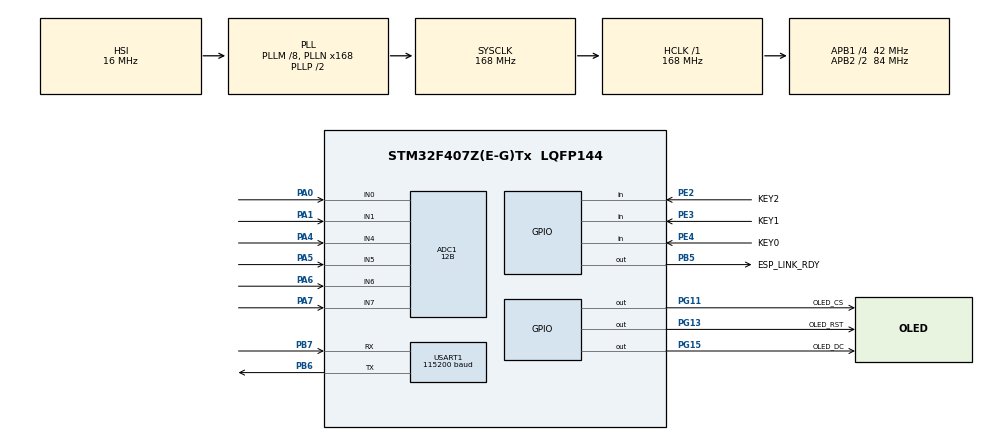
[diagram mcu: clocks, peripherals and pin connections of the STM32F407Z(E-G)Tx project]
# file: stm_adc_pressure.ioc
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ADC1.Channel-1\#ChannelRegularConversion=ADC_CHANNEL_0
ADC1.Channel-2\#ChannelRegularConversion=ADC_CHANNEL_1
ADC1.Channel-3\#ChannelRegularConversion=ADC_CHANNEL_4
ADC1.Channel-4\#ChannelRegularConversion=ADC_CHANNEL_5
ADC1.Channel-5\#ChannelRegularConversion=ADC_CHANNEL_6
ADC1.Channel-6\#ChannelRegularConversion=ADC_CHANNEL_7
ADC1.ClockPrescaler=ADC_CLOCK_SYNC_PCLK_DIV4
ADC1.ContinuousConvMode=DISABLE
ADC1.DMAContinuousRequests=ENABLE
ADC1.DataAlign=ADC_DATAALIGN_RIGHT
ADC1.DiscontinuousConvMode=DISABLE
ADC1.EOCSelection=ADC_EOC_SEQ_CONV
ADC1.EnableAnalogWatchDog=false
ADC1.ExternalTrigConv=ADC_EXTERNALTRIGCONV_T2_TRGO
ADC1.ExternalTrigConvEdge=ADC_EXTERNALTRIGCONVEDGE_RISING
ADC1.InjNumberOfConversion=0
ADC1.NbrOfConversion=6
ADC1.NbrOfConversionFlag=1
ADC1.Rank-1\#ChannelRegularConversion=1
ADC1.Rank-2\#ChannelRegularConversion=2
ADC1.Rank-3\#ChannelRegularConversion=3
ADC1.Rank-4\#ChannelRegularConversion=4
ADC1.Rank-5\#ChannelRegularConversion=5
ADC1.Rank-6\#ChannelRegularConversion=6
ADC1.Resolution=ADC_RESOLUTION_12B
ADC1.SamplingTime-1\#ChannelRegularConversion=ADC_SAMPLETIME_56CYCLES
ADC1.SamplingTime-2\#ChannelRegularConversion=ADC_SAMPLETIME_56CYCLES
ADC1.SamplingTime-3\#ChannelRegularConversion=ADC_SAMPLETIME_56CYCLES
ADC1.SamplingTime-4\#ChannelRegularConversion=ADC_SAMPLETIME_56CYCLES
ADC1.SamplingTime-5\#ChannelRegularConversion=ADC_SAMPLETIME_56CYCLES
ADC1.SamplingTime-6\#ChannelRegularConversion=ADC_SAMPLETIME_56CYCLES
ADC1.ScanConvMode=ENABLE
ADC1.master=1
Dma.ADC1.0.Direction=DMA_PERIPH_TO_MEMORY
Dma.ADC1.0.FIFOMode=DMA_FIFOMODE_DISABLE
Dma.ADC1.0.Instance=DMA2_Stream0
Dma.ADC1.0.MemDataAlignment=DMA_MDATAALIGN_HALFWORD
Dma.ADC1.0.MemInc=DMA_MINC_ENABLE
Dma.ADC1.0.Mode=DMA_CIRCULAR
Dma.ADC1.0.PeriphDataAlignment=DMA_PDATAALIGN_HALFWORD
Dma.ADC1.0.PeriphInc=DMA_PINC_DISABLE
Dma.ADC1.0.Priority=DMA_PRIORITY_VERY_HIGH
Dma.Request1=SPI2_RX
Dma.Request2=SPI2_TX
Dma.Request0=ADC1
Dma.SPI2_RX.0.Direction=DMA_PERIPH_TO_MEMORY
Dma.SPI2_RX.0.FIFOMode=DMA_FIFOMODE_DISABLE
Dma.SPI2_RX.0.Instance=DMA1_Stream3
Dma.SPI2_RX.0.MemDataAlignment=DMA_MDATAALIGN_BYTE
Dma.SPI2_RX.0.MemInc=DMA_MINC_ENABLE
Dma.SPI2_RX.0.Mode=DMA_NORMAL
Dma.SPI2_RX.0.PeriphDataAlignment=DMA_PDATAALIGN_BYTE
Dma.SPI2_RX.0.PeriphInc=DMA_PINC_DISABLE
Dma.SPI2_RX.0.Priority=DMA_PRIORITY_HIGH
Dma.SPI2_TX.1.Direction=DMA_MEMORY_TO_PERIPH
Dma.SPI2_TX.1.FIFOMode=DMA_FIFOMODE_DISABLE
Dma.SPI2_TX.1.Instance=DMA1_Stream4
Dma.SPI2_TX.1.MemDataAlignment=DMA_MDATAALIGN_BYTE
Dma.SPI2_TX.1.MemInc=DMA_MINC_ENABLE
Dma.SPI2_TX.1.Mode=DMA_NORMAL
Dma.SPI2_TX.1.PeriphDataAlignment=DMA_PDATAALIGN_BYTE
Dma.SPI2_TX.1.PeriphInc=DMA_PINC_DISABLE
Dma.SPI2_TX.1.Priority=DMA_PRIORITY_HIGH
FREERTOS.Tasks01=defaultTask,24,128,StartDefaultTask,Default,NULL,Dynamic,NULL,NULL
Mcu.Family=STM32F4
Mcu.Name=STM32F407Z(E-G)Tx
Mcu.Package=LQFP144
NVIC.DMA1_Stream3_IRQn=true\:5\:0\:false\:false\:true\:true\:false\:true\:true
NVIC.DMA1_Stream4_IRQn=true\:5\:0\:false\:false\:true\:true\:false\:true\:true
NVIC.DMA2_Stream0_IRQn=true\:5\:0\:false\:false\:true\:true\:false\:true\:true
NVIC.PriorityGroup=NVIC_PRIORITYGROUP_4
PC10.GPIO_Label=OLED_SCLK
PC10.Signal=SPI3_SCK
PC12.GPIO_Label=OLED_SDIN
PC12.Signal=SPI3_MOSI
PA0-WKUP.Signal=ADCx_IN0
PA1.Signal=ADCx_IN1
PA13.Mode=Serial_Wire
PA13.Signal=SYS_JTMS-SWDIO
PA14.Mode=Serial_Wire
PA14.Signal=SYS_JTCK-SWCLK
PA4.Signal=ADCx_IN4
PA5.Signal=ADCx_IN5
PA6.Signal=ADCx_IN6
PA7.Signal=ADCx_IN7
PB5.GPIO_Label=ESP_LINK_RDY
PB5.GPIO_Speed=GPIO_SPEED_FREQ_VERY_HIGH
PB5.PinState=GPIO_PIN_RESET
PB5.Signal=GPIO_Output
PB6.Mode=Asynchronous
PB6.Signal=USART1_TX
PB7.Mode=Asynchronous
PB7.Signal=USART1_RX
PB12.Signal=SPI2_NSS
PB13.Signal=SPI2_SCK
PB14.Signal=SPI2_MISO
PB15.Signal=SPI2_MOSI
PE2.GPIO_Label=KEY2
PE2.GPIO_PuPd=GPIO_PULLUP
PE2.Signal=GPIO_Input
PE3.GPIO_Label=KEY1
PE3.GPIO_PuPd=GPIO_PULLUP
PE3.Signal=GPIO_Input
PE4.GPIO_Label=KEY0
PE4.GPIO_PuPd=GPIO_PULLUP
PE4.Signal=GPIO_Input
PG11.GPIO_Label=OLED_CS
PG11.GPIO_Speed=GPIO_SPEED_FREQ_VERY_HIGH
PG11.PinState=GPIO_PIN_SET
PG11.Signal=GPIO_Output
PG13.GPIO_Label=OLED_RST
PG13.GPIO_Speed=GPIO_SPEED_FREQ_VERY_HIGH
PG13.PinState=GPIO_PIN_SET
PG13.Signal=GPIO_Output
PG15.GPIO_Label=OLED_DC
PG15.GPIO_Speed=GPIO_SPEED_FREQ_VERY_HIGH
PG15.PinState=GPIO_PIN_SET
PG15.Signal=GPIO_Output
PH0-OSC_IN.Mode=HSE-External-Oscillator
PH0-OSC_IN.Signal=RCC_OSC_IN
PH1-OSC_OUT.Mode=HSE-External-Oscillator
PH1-OSC_OUT.Signal=RCC_OSC_OUT
ProjectManager.HeapSize=0x200
ProjectManager.StackSize=0x400
ProjectManager.TargetToolchain=CMake
TIM2.AutoReloadPreload=TIM_AUTORELOAD_PRELOAD_DISABLE
TIM2.ClockDivision=TIM_CLOCKDIVISION_DIV1
TIM2.CounterMode=TIM_COUNTERMODE_UP
TIM2.ClockSource=TIM_CLOCKSOURCE_INTERNAL
TIM2.MasterOutputTrigger=TIM_TRGO_UPDATE
TIM2.MasterSlaveMode=TIM_MASTERSLAVEMODE_DISABLE
TIM2.Period=9999
TIM2.Prescaler=83
RCC.48MHZClocksFreq_Value=84000000
RCC.AHBFreq_Value=168000000
RCC.APB1CLKDivider=RCC_HCLK_DIV4
RCC.APB1Freq_Value=42000000
RCC.APB1TimFreq_Value=84000000
RCC.APB2CLKDivider=RCC_HCLK_DIV2
RCC.APB2Freq_Value=84000000
RCC.APB2TimFreq_Value=168000000
RCC.CortexFreq_Value=168000000
RCC.HCLKFreq_Value=168000000
RCC.HSE_VALUE=25000000
RCC.HSI_VALUE=16000000
RCC.LSE_VALUE=32768
RCC.PLLM=8
RCC.PLLN=168
RCC.SYSCLKFreq_VALUE=168000000
RCC.SYSCLKSource=RCC_SYSCLKSOURCE_PLLCLK
RCC.VCOOutputFreq_Value=336000000
SPI2.CLKPhase=SPI_PHASE_1EDGE
SPI2.CLKPolarity=SPI_POLARITY_LOW
SPI2.CRCCalculation=SPI_CRCCALCULATION_DISABLE
SPI2.CRCPolynomial=10
SPI2.DataSize=SPI_DATASIZE_8BIT
SPI2.Direction=SPI_DIRECTION_2LINES
SPI2.FirstBit=SPI_FIRSTBIT_MSB
SPI2.Mode=SPI_MODE_SLAVE
SPI2.NSS=SPI_NSS_HARD_INPUT
SPI2.TIMode=SPI_TIMODE_DISABLE
SPI2.VirtualType=VM_SLAVE
SPI3.BaudRatePrescaler=SPI_BAUDRATEPRESCALER_8
SPI3.CLKPhase=SPI_PHASE_1EDGE
SPI3.CLKPolarity=SPI_POLARITY_LOW
SPI3.CRCCalculation=SPI_CRCCALCULATION_DISABLE
SPI3.CRCPolynomial=10
SPI3.DataSize=SPI_DATASIZE_8BIT
SPI3.Direction=SPI_DIRECTION_1LINE
SPI3.FirstBit=SPI_FIRSTBIT_MSB
SPI3.Mode=SPI_MODE_MASTER
SPI3.NSS=SPI_NSS_SOFT
SPI3.TIMode=SPI_TIMODE_DISABLE
SPI3.VirtualType=VM_MASTER
SH.ADCx_IN0.0=ADC1_IN0,IN0
SH.ADCx_IN1.0=ADC1_IN1,IN1
SH.ADCx_IN4.0=ADC1_IN4,IN4
SH.ADCx_IN5.0=ADC1_IN5,IN5
SH.ADCx_IN6.0=ADC1_IN6,IN6
SH.ADCx_IN7.0=ADC1_IN7,IN7
USART1.BaudRate=115200
USART1.HardwareFlowControl=UART_HWCONTROL_NONE
USART1.Mode=MODE_TX_RX
USART1.OverSampling=UART_OVERSAMPLING_16
USART1.Parity=UART_PARITY_NONE
USART1.StopBits=UART_STOPBITS_1
USART1.VirtualMode=VM_ASYNC
USART1.VirtualMode-Asynchronous=VM_ASYNC
USART1.WordLength=UART_WORDLENGTH_8B
VP_FREERTOS_VS_CMSIS_V2.Mode=CMSIS_V2
board=custom

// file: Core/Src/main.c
/* USER CODE BEGIN Header */
/**
  ******************************************************************************
  * @file           : main.c
  * @brief          : Main program body
  ******************************************************************************
  * @attention
  *
  * Copyright (c) 2026 STMicroelectronics.
  * All rights reserved.
  *
  * This software is licensed under terms that can be found in the LICENSE file
  * in the root directory of this software component.
  * If no LICENSE file comes with this software, it is provided AS-IS.
  *
  ******************************************************************************
  */
/* USER CODE END Header */
#include "main.h"
#include "cmsis_os.h"
#include "adc.h"
#include "dma.h"
#include "spi.h"
#include "tim.h"
#include "usart.h"
#include "gpio.h"

/* USER CODE BEGIN Includes */
#include "app_main.h"

/* USER CODE END Includes */

void SystemClock_Config(void);
void MX_FREERTOS_Init(void);

int main(void)
{

  /* MCU Configuration--------------------------------------------------------*/

  /* Reset of all peripherals, Initializes the Flash interface and the Systick. */
  HAL_Init();

  /* Configure the system clock */
  SystemClock_Config();

  /* Initialize all configured peripherals */
  MX_GPIO_Init();
  MX_DMA_Init();
  MX_ADC1_Init();
  MX_TIM2_Init();
  MX_SPI2_Init();
  MX_SPI3_Init();
  MX_USART1_UART_Init();
  /* USER CODE BEGIN 2 */

  App_Init();

  /* USER CODE END 2 */

  /* Init scheduler */
  osKernelInitialize();  /* Call init function for freertos objects (in cmsis_os2.c) */
  MX_FREERTOS_Init();

  /* Start scheduler */
  osKernelStart();

  /* We should never get here as control is now taken by the scheduler */

  /* Infinite loop */
  while (1)
  {

    /* USER CODE BEGIN 3 */
    App_Run();
  }
  /* USER CODE END 3 */
}

void SystemClock_Config(void)
{
  RCC_OscInitTypeDef RCC_OscInitStruct = {0};
  RCC_ClkInitTypeDef RCC_ClkInitStruct = {0};

  /** Configure the main internal regulator output voltage
  */
  __HAL_RCC_PWR_CLK_ENABLE();
  __HAL_PWR_VOLTAGESCALING_CONFIG(PWR_REGULATOR_VOLTAGE_SCALE1);

  /** Initializes the RCC Oscillators according to the specified parameters
  * in the RCC_OscInitTypeDef structure.
  */
  RCC_OscInitStruct.OscillatorType = RCC_OSCILLATORTYPE_HSI;
  RCC_OscInitStruct.HSIState = RCC_HSI_ON;
  RCC_OscInitStruct.HSICalibrationValue = RCC_HSICALIBRATION_DEFAULT;
  RCC_OscInitStruct.PLL.PLLState = RCC_PLL_ON;
  RCC_OscInitStruct.PLL.PLLSource = RCC_PLLSOURCE_HSI;
  RCC_OscInitStruct.PLL.PLLM = 8;
  RCC_OscInitStruct.PLL.PLLN = 168;
  RCC_OscInitStruct.PLL.PLLP = RCC_PLLP_DIV2;
  RCC_OscInitStruct.PLL.PLLQ = 4;
  if (HAL_RCC_OscConfig(&RCC_OscInitStruct) != HAL_OK)
  {
    Error_Handler();
  }

  /** Initializes the CPU, AHB and APB buses clocks
  */
  RCC_ClkInitStruct.ClockType = RCC_CLOCKTYPE_HCLK|RCC_CLOCKTYPE_SYSCLK
                              |RCC_CLOCKTYPE_PCLK1|RCC_CLOCKTYPE_PCLK2;
  RCC_ClkInitStruct.SYSCLKSource = RCC_SYSCLKSOURCE_PLLCLK;
  RCC_ClkInitStruct.AHBCLKDivider = RCC_SYSCLK_DIV1;
  RCC_ClkInitStruct.APB1CLKDivider = RCC_HCLK_DIV4;
  RCC_ClkInitStruct.APB2CLKDivider = RCC_HCLK_DIV2;

  if (HAL_RCC_ClockConfig(&RCC_ClkInitStruct, FLASH_LATENCY_5) != HAL_OK)
  {
    Error_Handler();
  }
}

void Error_Handler(void)
{
  __disable_irq();
  while (1)
  {
  }
}

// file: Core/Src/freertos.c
/* USER CODE BEGIN Header */
/**
  ******************************************************************************
  * File Name          : freertos.c
  * Description        : Code for freertos applications
  ******************************************************************************
  * @attention
  *
  * Copyright (c) 2026 STMicroelectronics.
  * All rights reserved.
  *
  * This software is licensed under terms that can be found in the LICENSE file
  * in the root directory of this software component.
  * If no LICENSE file comes with this software, it is provided AS-IS.
  *
  ******************************************************************************
  */
/* USER CODE END Header */

#include "FreeRTOS.h"
#include "task.h"
#include "main.h"
#include "cmsis_os.h"

/* USER CODE BEGIN Includes */
#include "app_main.h"

/* USER CODE END Includes */

/* Definitions for defaultTask */
osThreadId_t defaultTaskHandle;
const osThreadAttr_t defaultTask_attributes = {
  .name = "defaultTask",
  .stack_size = 128 * 4,
  .priority = (osPriority_t) osPriorityNormal,
};

void StartDefaultTask(void *argument);

void MX_FREERTOS_Init(void); /* (MISRA C 2004 rule 8.1) */

void MX_FREERTOS_Init(void) {

  /* Create the thread(s) */
  /* creation of defaultTask */
  defaultTaskHandle = osThreadNew(StartDefaultTask, NULL, &defaultTask_attributes);

  /* USER CODE BEGIN RTOS_THREADS */
  App_RtosInit();
  /* USER CODE END RTOS_THREADS */

}

void StartDefaultTask(void *argument)
{
  /* USER CODE BEGIN StartDefaultTask */
  (void)argument;
  osThreadExit();
  /* USER CODE END StartDefaultTask */
}
